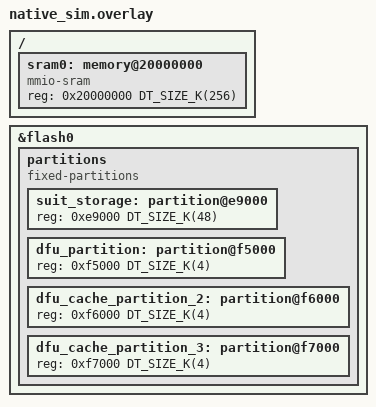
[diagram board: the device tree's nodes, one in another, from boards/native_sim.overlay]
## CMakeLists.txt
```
#
# Copyright (c) 2023 Nordic Semiconductor ASA
#
# SPDX-License-Identifier: LicenseRef-Nordic-5-Clause
#

cmake_minimum_required(VERSION 3.20.0)

find_package(Zephyr REQUIRED HINTS $ENV{ZEPHYR_BASE})

project(integration_test_fetch)
include(../cmake/test_template.cmake)

target_include_directories(app PRIVATE mocks)

zephyr_library_link_libraries(suit_memptr_storage_interface)
zephyr_library_link_libraries(suit_platform_interface)
zephyr_library_link_libraries(suit_ipuc)

zephyr_library_link_libraries_ifdef(CONFIG_TEST_SUIT_PLATFORM_FETCH_VARIANT_APP suit_memory_layout_interface)
zephyr_library_link_libraries_ifdef(CONFIG_TEST_SUIT_PLATFORM_FETCH_VARIANT_SDFW suit_decrypt_test_utils)
zephyr_library_link_libraries_ifdef(CONFIG_TEST_SUIT_PLATFORM_FETCH_VARIANT_SDFW suit_stream_filters_interface)

zephyr_compile_definitions(CONFIG_SOC_NRF54H20_CPUAPP)
```

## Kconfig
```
#
# Copyright (c) 2024 Nordic Semiconductor ASA
#
# SPDX-License-Identifier: LicenseRef-Nordic-5-Clause
#

# Include and define MOCK_* Kconfigs
rsource "../mocks/Kconfig"
rsource "../tests/Kconfig"

choice TEST_SUIT_PLATFORM_FETCH_VARIANT
	prompt "SUIT platform implementation variant to test"
	default TEST_SUIT_PLATFORM_FETCH_VARIANT_SDFW

config TEST_SUIT_PLATFORM_FETCH_VARIANT_APP
	bool "Local or application"
	depends on SUIT_PLATFORM_VARIANT_APP
	select FLASH_IPUC
	select SUIT_ENVELOPE_INFO
	select SUIT_CACHE_RW
	select SUIT_STREAM_SINK_CACHE
	select SUIT_STREAM_FETCH_SOURCE_MGR

config TEST_SUIT_PLATFORM_FETCH_VARIANT_SDFW
	bool "Bootloader or SDFW"
	depends on SUIT_PLATFORM_VARIANT_SDFW
	select MOCK_SDFW_ARBITER
	select SUIT_EXECUTION_MODE
	select SUIT_MCI
	select SUIT_STREAM_FILTER_DECRYPT
	select SUIT_CRYPTO
	select SUIT_STORAGE

endchoice # TEST_SUIT_PLATFORM_FETCH_VARIANT

if TEST_SUIT_PLATFORM_FETCH_VARIANT_APP

config SUIT_CACHE_SDFW_IPUC
	default y

config SUIT_CACHE_SDFW_IPUC_ID
	default 1

config SUIT_CACHE_APP_IPUC
	default y

config SUIT_CACHE_APP_IPUC_ID
	default 255

endif # TEST_SUIT_PLATFORM_FETCH_VARIANT_APP

source "Kconfig.zephyr"
```

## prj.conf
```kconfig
#
# Copyright (c) 2023 Nordic Semiconductor ASA
#
# SPDX-License-Identifier: LicenseRef-Nordic-5-Clause
#

CONFIG_ZTEST=y

CONFIG_SUIT=y
CONFIG_SUIT_PROCESSOR=y
CONFIG_SUIT_PLATFORM=y
CONFIG_SUIT_METADATA=y

CONFIG_SUIT_STREAM=y
CONFIG_SUIT_SINK_SELECTOR=y
CONFIG_SUIT_STREAM_SOURCE_CACHE=y
CONFIG_SUIT_STREAM_SOURCE_MEMPTR=y
CONFIG_SUIT_STREAM_SINK_FLASH=y
CONFIG_SUIT_STREAM_SINK_MEMPTR=y

CONFIG_SUIT_UTILS=y
CONFIG_SUIT_CACHE=y
CONFIG_SUIT_MEMPTR_STORAGE=y

CONFIG_ZCBOR=y
CONFIG_ZCBOR_CANONICAL=y

CONFIG_FLASH=y
CONFIG_FLASH_MAP=y

CONFIG_SUIT_IPUC=y
CONFIG_MOCK_SDFW_ARBITER=y
CONFIG_SUIT_STORAGE=y

CONFIG_SUIT_EXECUTION_MODE=y
CONFIG_SUIT_MCI=y
CONFIG_SUIT_STREAM_FILTER_DECRYPT=y
CONFIG_SUIT_CRYPTO=y
```

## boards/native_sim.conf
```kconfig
#
# Copyright (c) 2025 Nordic Semiconductor ASA
#
# SPDX-License-Identifier: LicenseRef-Nordic-5-Clause
#

CONFIG_FLASH_SIMULATOR=y
CONFIG_FLASH_SIMULATOR_DOUBLE_WRITES=y
```

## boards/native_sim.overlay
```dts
/*
 * Copyright (c) 2025 Nordic Semiconductor ASA
 *
 * SPDX-License-Identifier: LicenseRef-Nordic-5-Clause
 */

&flash0 {
	partitions {
		compatible = "fixed-partitions";
		#address-cells = <1>;
		#size-cells = <1>;

		suit_storage: partition@e9000 {
			reg = <0xe9000 DT_SIZE_K(48)>;
		};

		dfu_partition: partition@f5000 {
			reg = <0xf5000 DT_SIZE_K(4)>;
		};

		dfu_cache_partition_2: partition@f6000 {
			reg = <0xf6000 DT_SIZE_K(4)>;
		};

		dfu_cache_partition_3: partition@f7000 {
			reg = <0xf7000 DT_SIZE_K(4)>;
		};
	};
};

/ {
	sram0: memory@20000000 {
		compatible = "mmio-sram";
		reg = <0x20000000 DT_SIZE_K(256)>;
	};
};
```

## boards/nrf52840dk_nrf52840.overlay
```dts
/*
 * Copyright (c) 2025 Nordic Semiconductor ASA
 *
 * SPDX-License-Identifier: LicenseRef-Nordic-5-Clause
 */

&flash0 {
	partitions {
		compatible = "fixed-partitions";
		#address-cells = <1>;
		#size-cells = <1>;

		/* Use the last 48KB of NVM as suit storage. */
		suit_storage: partition@f4000 {
			reg = <0xf4000 DT_SIZE_K(48)>;
		};
	};
};
```

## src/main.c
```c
/*
 * Copyright (c) 2023 Nordic Semiconductor ASA
 *
 * SPDX-License-Identifier: LicenseRef-Nordic-5-Clause
 */

#include <zephyr/ztest.h>
#include <suit_platform.h>
#include <suit_memptr_storage.h>
#include <suit_platform_internal.h>
#include <suit_dfu_cache.h>

static uint8_t test_data[] = {0,  1,  2,  3,  4,  5,  6,  7,  8,  9,  10, 11, 12, 13, 14, 15,
			      16, 17, 18, 19, 20, 21, 22, 23, 24, 25, 26, 27, 28, 29, 30, 31,
			      32, 33, 34, 35, 36, 37, 38, 39, 40, 41, 42, 43, 44, 45, 46, 47,
			      48, 49, 50, 51, 52, 53, 54, 55, 56, 57, 58, 59, 60, 61, 62, 63};

/*
 * {
 *    "http://source1.com": h'4235623423462346456234623487723572702975',
 *    "http://source2.com.no": h'25672519384710',
 *    "ftp://altsource.com": h'92384859284720'
 * }
 */
static const uint8_t cache[] = {
	0xBF, 0x72, 0x68, 0x74, 0x74, 0x70, 0x3A, 0x2F, 0x2F, 0x73, 0x6F, 0x75, 0x72, 0x63, 0x65,
	0x31, 0x2E, 0x63, 0x6F, 0x6D, 0x54, 0x42, 0x35, 0x62, 0x34, 0x23, 0x46, 0x23, 0x46, 0x45,
	0x62, 0x34, 0x62, 0x34, 0x87, 0x72, 0x35, 0x72, 0x70, 0x29, 0x75, 0x75, 0x68, 0x74, 0x74,
	0x70, 0x3A, 0x2F, 0x2F, 0x73, 0x6F, 0x75, 0x72, 0x63, 0x65, 0x32, 0x2E, 0x63, 0x6F, 0x6D,
	0x2E, 0x6E, 0x6F, 0x47, 0x25, 0x67, 0x25, 0x19, 0x38, 0x47, 0x10, 0x73, 0x66, 0x74, 0x70,
	0x3A, 0x2F, 0x2F, 0x61, 0x6C, 0x74, 0x73, 0x6F, 0x75, 0x72, 0x63, 0x65, 0x2E, 0x63, 0x6F,
	0x6D, 0x47, 0x92, 0x38, 0x48, 0x59, 0x28, 0x47, 0x20, 0xFF};
static const size_t cache_len = sizeof(cache);

/*
 * {
 *    "http://databucket.com": h'4360021135853785764409444542662512368400086117',
 *    "http://storagehole.com": h'053714514299994946548928821768209760220451452304',
 *    "#file.bin": h'12358902317049812091623890476012378490701892365192830986701923'
 * }
 */
static const uint8_t cache2[] = {
	0xA3, 0x75, 0x68, 0x74, 0x74, 0x70, 0x3A, 0x2F, 0x2F, 0x64, 0x61, 0x74, 0x61, 0x62,
	0x75, 0x63, 0x6B, 0x65, 0x74, 0x2E, 0x63, 0x6F, 0x6D, 0x57, 0x43, 0x60, 0x02, 0x11,
	0x35, 0x85, 0x37, 0x85, 0x76, 0x44, 0x09, 0x44, 0x45, 0x42, 0x66, 0x25, 0x12, 0x36,
	0x84, 0x00, 0x08, 0x61, 0x17, 0x76, 0x68, 0x74, 0x74, 0x70, 0x3A, 0x2F, 0x2F, 0x73,
	0x74, 0x6F, 0x72, 0x61, 0x67, 0x65, 0x68, 0x6F, 0x6C, 0x65, 0x2E, 0x63, 0x6F, 0x6D,
	0x58, 0x18, 0x05, 0x37, 0x14, 0x51, 0x42, 0x99, 0x99, 0x49, 0x46, 0x54, 0x89, 0x28,
	0x82, 0x17, 0x68, 0x20, 0x97, 0x60, 0x22, 0x04, 0x51, 0x45, 0x23, 0x04, 0x69, 0x23,
	0x66, 0x69, 0x6C, 0x65, 0x2E, 0x62, 0x69, 0x6E, 0x58, 0x1F, 0x12, 0x35, 0x89, 0x02,
	0x31, 0x70, 0x49, 0x81, 0x20, 0x91, 0x62, 0x38, 0x90, 0x47, 0x60, 0x12, 0x37, 0x84,
	0x90, 0x70, 0x18, 0x92, 0x36, 0x51, 0x92, 0x83, 0x09, 0x86, 0x70, 0x19, 0x23};
static const size_t cache2_len = sizeof(cache2);

/* clang-format off */
static const uint8_t valid_manifest_component[] = {
	0x82, /* array: 2 elements */
		0x4c, /* byte string: 12 bytes */
			0x6b, /* string: 11 characters */
				'I', 'N', 'S', 'T', 'L', 'D', '_', 'M', 'F', 'S', 'T',
		0x50, /* byte string: 16 bytes */
			0x5b, 0x46, 0x9f, 0xd1, 0x90, 0xee, 0x53, 0x9c,
			0xa3, 0x18, 0x68, 0x1b, 0x03, 0x69, 0x5e, 0x36
};
/* clang-format on */

static struct zcbor_string valid_manifest_component_id = {
	.value = valid_manifest_component,
	.len = sizeof(valid_manifest_component),
};

static void setup_cache_with_sample_entries(void)
{
	struct dfu_cache dfu_caches;

	zassert_between_inclusive(2, 1, CONFIG_SUIT_CACHE_MAX_CACHES,
				  "Failed to prepare test fixture: cache istoo small");

	dfu_caches.pools[0].address = (uint8_t *)cache;
	dfu_caches.pools[0].size = (size_t)cache_len;

	dfu_caches.pools[1].address = (uint8_t *)cache2;
	dfu_caches.pools[1].size = (size_t)cache2_len;
	dfu_caches.pools_count = 2;

	suit_dfu_cache_deinitialize();

	suit_plat_err_t rc = suit_dfu_cache_initialize(&dfu_caches);

	zassert_equal(rc, SUIT_PLAT_SUCCESS, "Failed to initialize cache: %i", rc);
}

ZTEST_SUITE(fetch_tests, NULL, NULL, NULL, NULL, NULL);

ZTEST(fetch_tests, test_integrated_fetch_to_memptr_OK)
{
	suit_component_t component_handle;
	memptr_storage_handle_t handle = NULL;
	struct zcbor_string source = {.value = test_data, .len = sizeof(test_data)};
	/* [h'CAND_IMG', h'02'] */
	uint8_t valid_value[] = {0x82, 0x49, 0x68, 'C', 'A',  'N', 'D',
				 '_',  'I',  'M',  'G', 0x41, 0x02};

	struct zcbor_string valid_component_id = {
		.value = valid_value,
		.len = sizeof(valid_value),
	};

	int ret = suit_plat_create_component_handle(&valid_component_id, false, &component_handle);

	zassert_equal(ret, SUIT_SUCCESS, "create_component_handle failed - error %i", ret);

	ret = suit_plat_fetch_integrated(component_handle, &source, &valid_manifest_component_id,
					 NULL);
	zassert_equal(ret, SUIT_SUCCESS, "suit_plat_fetch failed - error %i", ret);

	ret = suit_plat_component_impl_data_get(component_handle, &handle);
	zassert_equal(ret, SUIT_SUCCESS, "suit_plat_component_impl_data_get failed - error %i",
		      ret);

	const uint8_t *payload;
	size_t payload_size = 0;

	ret = suit_memptr_storage_ptr_get(handle, &payload, &payload_size);
	zassert_equal(ret, SUIT_PLAT_SUCCESS, "storage.get failed - error %i", ret);
	zassert_equal(test_data, payload, "Retrieved payload doesn't mach test_data");
	zassert_equal(sizeof(test_data), payload_size,
		      "Retrieved payload_size doesn't mach size of test_data");

	ret = suit_plat_release_component_handle(component_handle);
	zassert_equal(ret, SUIT_SUCCESS, "Handle release failed - error %i", ret);
}

ZTEST(fetch_tests, test_fetch_to_memptr_OK)
{

	suit_component_t component_handle;
	struct zcbor_string uri = {.value = "http://databucket.com",
				   .len = sizeof("http://databucket.com")};
	/* [h'CAND_IMG', h'02'] */
	uint8_t valid_value[] = {0x82, 0x49, 0x68, 'C', 'A',  'N', 'D',
				 '_',  'I',  'M',  'G', 0x41, 0x02};

	struct zcbor_string valid_component_id = {
		.value = valid_value,
		.len = sizeof(valid_value),
	};

	int ret = suit_plat_create_component_handle(&valid_component_id, false, &component_handle);

	zassert_equal(ret, SUIT_SUCCESS, "create_component_handle failed - error %i", ret);

	setup_cache_with_sample_entries();

	ret = suit_plat_fetch(component_handle, &uri, &valid_manifest_component_id, NULL);
	zassert_equal(ret, SUIT_SUCCESS, "suit_plat_fetch failed - error %i", ret);

	ret = suit_plat_release_component_handle(component_handle);
	zassert_equal(ret, SUIT_SUCCESS, "Handle release failed - error %i", ret);

	suit_dfu_cache_deinitialize();
}

ZTEST(fetch_tests, test_fetch_to_memptr_NOK_uri_not_in_cache)
{
	suit_component_t component_handle;
	struct zcbor_string uri = {.value = "http://databucket.no",
				   .len = sizeof("http://databucket.no")};
	/* [h'CAND_IMG', h'02'] */
	uint8_t valid_value[] = {0x82, 0x49, 0x68, 'C', 'A',  'N', 'D',
				 '_',  'I',  'M',  'G', 0x41, 0x02};

	struct zcbor_string valid_component_id = {
		.value = valid_value,
		.len = sizeof(valid_value),
	};

	int ret = suit_plat_create_component_handle(&valid_component_id, false, &component_handle);

	zassert_equal(ret, SUIT_SUCCESS, "create_component_handle failed - error %i", ret);

	setup_cache_with_sample_entries();

	ret = suit_plat_fetch(component_handle, &uri, &valid_manifest_component_id, NULL);
	zassert_equal(ret, SUIT_SUCCESS,
		      "suit_plat_fetch should succeed - supplied uri is not in cache, "
		      "treated as empty payload");

	ret = suit_plat_release_component_handle(component_handle);
	zassert_equal(ret, SUIT_SUCCESS, "Handle release failed - error %i", ret);

	suit_dfu_cache_deinitialize();
}

ZTEST(fetch_tests, test_fetch_to_memptr_NOK_invalid_component_id)
{
	suit_component_t component_handle;
	struct zcbor_string uri = {.value = "http://databucket.com",
				   .len = sizeof("http://databucket.com")};
	/* [h'MEM', h'01', h'1A00080000', h'08'] */
	uint8_t valid_value[] = {0x84, 0x44, 0x63, 'M',	 'E',  'M',  0x41, 0x01,
				 0x45, 0x1A, 0x00, 0x08, 0x00, 0x00, 0x41, 0x08};

	struct zcbor_string valid_component_id = {
		.value = valid_value,
		.len = sizeof(valid_value),
	};

	int ret = suit_plat_create_component_handle(&valid_component_id, false, &component_handle);

	zassert_equal(ret, SUIT_SUCCESS, "create_component_handle failed - error %i", ret);

	setup_cache_with_sample_entries();

	ret = suit_plat_fetch(component_handle, &uri, &valid_manifest_component_id, NULL);
	zassert_not_equal(ret, SUIT_SUCCESS,
			  "suit_plat_fetch should have failed - invalid component_id");

	ret = suit_plat_release_component_handle(component_handle);
	zassert_equal(ret, SUIT_SUCCESS, "Handle release failed - error %i", ret);

	suit_dfu_cache_deinitialize();
}

ZTEST(fetch_tests, test_integrated_fetch_to_memptr_NOK_data_ptr_NULL)
{
	suit_component_t component_handle;
	struct zcbor_string source = {.value = NULL, .len = sizeof(test_data)};
	/* [h'CAND_IMG', h'02'] */
	uint8_t valid_value[] = {0x82, 0x49, 0x68, 'C', 'A',  'N', 'D',
				 '_',  'I',  'M',  'G', 0x41, 0x02};

	struct zcbor_string valid_component_id = {
		.value = valid_value,
		.len = sizeof(valid_value),
	};

	int ret = suit_plat_create_component_handle(&valid_component_id, false, &component_handle);

	zassert_equal(ret, SUIT_SUCCESS, "create_component_handle failed - error %i", ret);

	ret = suit_plat_fetch_integrated(component_handle, &source, &valid_manifest_component_id,
					 NULL);
	zassert_not_equal(ret, SUIT_SUCCESS,
			  "suit_plat_fetch should have failed - NULL data pointer");

	ret = suit_plat_release_component_handle(component_handle);
	zassert_equal(ret, SUIT_SUCCESS, "Handle release failed - error %i", ret);
}

ZTEST(fetch_tests, test_integrated_fetch_to_memptr_NOK_data_size_zero)
{
	suit_component_t component_handle;
	struct zcbor_string source = {.value = test_data, .len = 0};
	/* [h'CAND_IMG', h'02'] */
	uint8_t valid_value[] = {0x82, 0x49, 0x68, 'C', 'A',  'N', 'D',
				 '_',  'I',  'M',  'G', 0x41, 0x02};

	struct zcbor_string valid_component_id = {
		.value = valid_value,
		.len = sizeof(valid_value),
	};

	int ret = suit_plat_create_component_handle(&valid_component_id, false, &component_handle);

	zassert_equal(ret, SUIT_SUCCESS, "create_component_handle failed - error %i", ret);

	ret = suit_plat_fetch_integrated(component_handle, &source, &valid_manifest_component_id,
					 NULL);
	zassert_not_equal(ret, SUIT_SUCCESS, "suit_plat_fetch should have failed - data size 0");

	ret = suit_plat_release_component_handle(component_handle);
	zassert_equal(ret, SUIT_SUCCESS, "Handle release failed - error %i", ret);
}

ZTEST(fetch_tests, test_integrated_fetch_to_memptr_NOK_handle_NULL)
{
	suit_component_t component_handle;
	struct zcbor_string source = {.value = test_data, .len = sizeof(test_data)};
	/* [h'CAND_IMG', h'02'] */
	uint8_t valid_value[] = {0x82, 0x49, 0x68, 'C', 'A',  'N', 'D',
				 '_',  'I',  'M',  'G', 0x41, 0x02};

	struct zcbor_string valid_component_id = {
		.value = valid_value,
		.len = sizeof(valid_value),
	};

	int ret = suit_plat_create_component_handle(&valid_component_id, false, &component_handle);

	zassert_equal(ret, SUIT_SUCCESS, "create_component_handle failed - error %i", ret);

	ret = suit_plat_fetch_integrated(component_handle, &source, &valid_manifest_component_id,
					 NULL);
	zassert_equal(ret, SUIT_SUCCESS, "suit_plat_fetch failed - error %i", ret);

	const uint8_t *payload;
	size_t payload_size = 0;

	ret = suit_memptr_storage_ptr_get(NULL, &payload, &payload_size);
	zassert_not_equal(ret, SUIT_PLAT_SUCCESS,
			  "suit_memptr_storage_get should failed - handle NULL");

	ret = suit_plat_release_component_handle(component_handle);
	zassert_equal(ret, SUIT_SUCCESS, "Handle release failed - error %i", ret);
}
```

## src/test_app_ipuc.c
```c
/*
 * Copyright (c) 2025 Nordic Semiconductor ASA
 *
 * SPDX-License-Identifier: LicenseRef-Nordic-5-Clause
 */

#ifdef CONFIG_TEST_SUIT_PLATFORM_FETCH_VARIANT_APP
#include <zephyr/ztest.h>
#include <suit_platform.h>
#include <dfu/suit_dfu_fetch_source.h>
#include <mock_suit_ipuc.h>
#include <zephyr/fff.h>
#include <suit_dfu_cache_rw.h>
#include <drivers/flash/flash_ipuc.h>
#include <suit_plat_mem_util.h>

#if IS_ENABLED(CONFIG_FLASH)
#if (DT_NODE_EXISTS(DT_CHOSEN(zephyr_flash_controller)))
#define SUIT_PLAT_INTERNAL_NVM_DEV DEVICE_DT_GET(DT_CHOSEN(zephyr_flash_controller))
#else
#define SUIT_PLAT_INTERNAL_NVM_DEV DEVICE_DT_GET(DT_CHOSEN(zephyr_flash))
#endif
#else
#define SUIT_PLAT_INTERNAL_NVM_DEV NULL
#endif

static const uint8_t test_data[] = {0,	1,  2,	3,  4,	5,  6,	7,  8,	9,  10, 11, 12, 13, 14, 15,
				    16, 17, 18, 19, 20, 21, 22, 23, 24, 25, 26, 27, 28, 29, 30, 31,
				    32, 33, 34, 35, 36, 37, 38, 39, 40, 41, 42, 43, 44, 45, 46, 47,
				    48, 49, 50, 51, 52, 53, 54, 55, 56, 57, 58, 59, 60, 61, 62, 63};
static const uint8_t test_data_sdfw[] = {'S', 'D', 'F', 'W', '.', 'b', 'i', 'n'};
static const uint8_t test_data_scfw[] = {'S', 'y', 's', 'C', 't', 'r', 'l', '.', 'b', 'i', 'n'};

/* clang-format off */
static const uint8_t component_rad_0x80000_0x1000[] = {
	0x84, /* array(4) */
		0x44, /* bstr(4) */
			0x63, /* text(3) */
				'M', 'E', 'M',
		0x41, /* bstr(1) */
			0x20, /* Data */
		0x45, /* bstr(5) */
			0x1a, /* uint32 */
				0x00, 0x08, 0x00, 0x00,
		0x43, /* bstr(3) */
			0x19, /* uint16 */
				0x10, 0x00,
};
static const uint8_t component_app_0x90000_0x1000[] = {
	0x84, /* array(4) */
		0x44, /* bstr(4) */
			0x63, /* text(3) */
				'M', 'E', 'M',
		0x41, /* bstr(1) */
			0x20, /* Data */
		0x45, /* bstr(5) */
			0x1a, /* uint32 */
				0x00, 0x09, 0x00, 0x00,
		0x43, /* bstr(3) */
			0x19, /* uint16 */
				0x10, 0x00,
};
/* clang-format on */

static suit_plat_err_t suit_ipuc_get_count_single_fake_func(size_t *count)
{
	zassert_not_null(count, "Caller must provide non-Null pointer");

	*count = 1;

	return SUIT_PLAT_SUCCESS;
}

static suit_plat_err_t
suit_ipuc_get_info_0x80000_0x1000_fake_func(size_t idx, struct zcbor_string *component_id,
					    suit_manifest_role_t *role)
{
	zassert_not_null(component_id, "Caller must provide non-Null pointer to read component_id");
	zassert_not_null(role, "Caller must provide non-Null pointer to read role");
	zassert_equal(idx, 0, "Unexpected idx value");

	component_id->value = component_rad_0x80000_0x1000;
	component_id->len = sizeof(component_rad_0x80000_0x1000);
	*role = SUIT_MANIFEST_RAD_LOCAL_1;

	return SUIT_PLAT_SUCCESS;
}

static suit_plat_err_t suit_ipuc_write_rad_fake_func(struct zcbor_string *component_id,
						     size_t offset, uintptr_t buffer,
						     size_t chunk_size, bool last_chunk)
{
	zassert_not_null(component_id, "Caller must provide non-Null pointer to read component_id");
	zassert_equal(component_id->len, sizeof(component_rad_0x80000_0x1000),
		      "Invalid component ID length passed");
	zassert_equal(memcmp(component_id->value, component_rad_0x80000_0x1000, component_id->len),
		      0, "Invalid component ID value passed");

	return SUIT_PLAT_SUCCESS;
}

static suit_plat_err_t suit_ipuc_get_count_fake_func(size_t *count)
{
	zassert_not_null(count, "Caller must provide non-Null pointer");

	*count = 2;

	return SUIT_PLAT_SUCCESS;
}

static suit_plat_err_t suit_ipuc_get_info_fake_func(size_t idx, struct zcbor_string *component_id,
						    suit_manifest_role_t *role)
{
	zassert_not_null(component_id, "Caller must provide non-Null pointer to read component_id");
	zassert_not_null(role, "Caller must provide non-Null pointer to read role");
	zassert_true(idx < 2, "Unexpected idx value");

	if (idx == 0) {
		component_id->value = component_rad_0x80000_0x1000;
		component_id->len = sizeof(component_rad_0x80000_0x1000);
		*role = SUIT_MANIFEST_RAD_LOCAL_1;
	} else if (idx == 1) {
		component_id->value = component_app_0x90000_0x1000;
		component_id->len = sizeof(component_app_0x90000_0x1000);
		*role = SUIT_MANIFEST_APP_LOCAL_1;
	}

	return SUIT_PLAT_SUCCESS;
}

static suit_plat_err_t suit_ipuc_write_fake_func(struct zcbor_string *component_id, size_t offset,
						 uintptr_t buffer, size_t chunk_size,
						 bool last_chunk)
{
	zassert_not_null(component_id, "Caller must provide non-Null pointer to read component_id");
	zassert_equal(component_id->len, sizeof(component_app_0x90000_0x1000),
		      "Invalid component ID length passed");
	zassert_equal(memcmp(component_id->value, component_app_0x90000_0x1000, component_id->len),
		      0, "Invalid component ID value passed");

	zassert_equal(flash_write(SUIT_PLAT_INTERNAL_NVM_DEV, 0x90000 + offset, (uint8_t *)buffer,
				  chunk_size),
		      0, "Unable to modify NVM to match requested changes");

	return SUIT_PLAT_SUCCESS;
}

static int fetch_request_fn(const uint8_t *uri, size_t uri_length, uint32_t session_id)
{
	int rc = 0;

	if (((uri_length == sizeof("http://databucket.com")) &&
	     memcmp(uri, "http://databucket.com", uri_length) == 0)) {
		zassert_equal(uri_length, sizeof("http://databucket.com"),
			      "Unexpected URI length: %d", uri_length);
		zassert_equal(memcmp(uri, "http://databucket.com", uri_length), 0,
			      "Unexpected URI value");
		rc = suit_dfu_fetch_source_write_fetched_data(session_id, test_data,
							      sizeof(test_data));
	} else if (((uri_length == sizeof("http://databucket.com/sdfw.bin")) &&
		    memcmp(uri, "http://databucket.com/sdfw.bin", uri_length) == 0)) {
		zassert_equal(uri_length, sizeof("http://databucket.com/sdfw.bin"),
			      "Unexpected URI length: %d", uri_length);
		zassert_equal(memcmp(uri, "http://databucket.com/sdfw.bin", uri_length), 0,
			      "Unexpected URI value");
		rc = suit_dfu_fetch_source_write_fetched_data(session_id, test_data_sdfw,
							      sizeof(test_data_sdfw));
	} else if (((uri_length == sizeof("http://databucket.com/scfw.bin")) &&
		    memcmp(uri, "http://databucket.com/scfw.bin", uri_length) == 0)) {
		zassert_equal(uri_length, sizeof("http://databucket.com/scfw.bin"),
			      "Unexpected URI length: %d", uri_length);
		zassert_equal(memcmp(uri, "http://databucket.com/scfw.bin", uri_length), 0,
			      "Unexpected URI value");
		rc = suit_dfu_fetch_source_write_fetched_data(session_id, test_data_scfw,
							      sizeof(test_data_scfw));
	} else {
		zassert_true(false, "Unsupporte URI value");
	}

	if (rc != 0) {
		return SUIT_PLAT_ERR_CRASH;
	}

	return SUIT_PLAT_SUCCESS;
}

static void test_before(void *data)
{
	/* Reset mocks */
	mock_suit_ipuc_reset();

	/* Reset common FFF internal structures */
	FFF_RESET_HISTORY();

	/* Erase NVM area */
	zassert_equal(flash_erase(SUIT_PLAT_INTERNAL_NVM_DEV, 0x90000, 0x1000), 0,
		      "Unable to erase NVM before test execution");

	/* Load IPUCs as SUIT caches */
	suit_ipuc_get_count_fake.custom_fake = suit_ipuc_get_count_fake_func;
	suit_ipuc_get_info_fake.custom_fake = suit_ipuc_get_info_fake_func;

	suit_dfu_cache_rw_init();
	zassert_equal(suit_dfu_cache_0_resize(), SUIT_PLAT_SUCCESS,
		      "Failed to initialize SUIT cache before test execution.");
	zassert_equal(suit_ipuc_get_count_fake.call_count, 2,
		      "Incorrect number of suit_ipuc_get_count() calls (%d)",
		      suit_ipuc_get_count_fake.call_count);
	/* 2x ((count: search for max) + (info of the max)) */
	zassert_equal(suit_ipuc_get_info_fake.call_count, 6,
		      "Incorrect number of suit_ipuc_get_info() calls (%d)",
		      suit_ipuc_get_info_fake.call_count);
	/* Initialization routine must not erase IPUC areas. */
	zassert_equal(suit_ipuc_write_setup_fake.call_count, 0,
		      "Incorrect number of suit_ipuc_write_setup() calls (%d)",
		      suit_ipuc_write_setup_fake.call_count);
	/* Reset mocks */
	mock_suit_ipuc_reset();

	/* Reset common FFF internal structures */
	FFF_RESET_HISTORY();
}

ZTEST_SUITE(fetch_app_mem_tests, NULL, NULL, test_before, NULL, NULL);

ZTEST(fetch_app_mem_tests, test_fetch_to_ipuc_mem_OK)
{
	struct zcbor_string uri = {.value = "http://databucket.com",
				   .len = sizeof("http://databucket.com")};
	/* Create handle that will be used as destination */
	suit_component_t dst_handle;
	/* [h'MEM', h'20', h'1A00080000', h'191000'] */
	uint8_t valid_dst_value[] = {0x84, 0x44, 0x63, 'M',  'E',  'M',	 0x41, 0x20, 0x45,
				     0x1A, 0x00, 0x08, 0x00, 0x00, 0x43, 0x19, 0x10, 0x00};

	struct zcbor_string valid_dst_component_id = {
		.value = valid_dst_value,
		.len = sizeof(valid_dst_value),
	};

	suit_ipuc_get_count_fake.custom_fake = suit_ipuc_get_count_single_fake_func;
	suit_ipuc_get_info_fake.custom_fake = suit_ipuc_get_info_0x80000_0x1000_fake_func;
	suit_ipuc_write_setup_fake.return_val = SUIT_PLAT_SUCCESS;
	suit_ipuc_write_fake.custom_fake = suit_ipuc_write_rad_fake_func;

	zassert_equal(suit_dfu_fetch_source_register(fetch_request_fn), SUIT_PLAT_SUCCESS,
		      "Failed to register fetch source mock");

	int ret = suit_plat_create_component_handle(&valid_dst_component_id, false, &dst_handle);

	zassert_equal(ret, SUIT_SUCCESS, "create_component_handle failed - error %i", ret);

	ret = suit_plat_fetch(dst_handle, &uri, &valid_dst_component_id, NULL);
	zassert_equal(ret, SUIT_SUCCESS, "suit_plat_fetch failed - error %i", ret);

	/* Fetch operation validation. */
	zassert_equal(suit_ipuc_get_count_fake.call_count, 2,
		      "Incorrect number of suit_ipuc_get_count() calls (%d)",
		      suit_ipuc_get_count_fake.call_count);
	zassert_equal(suit_ipuc_get_info_fake.call_count, 2,
		      "Incorrect number of suit_ipuc_get_info() calls (%d)",
		      suit_ipuc_get_info_fake.call_count);
	/* Write into MEM IPUC. */
	zassert_equal(suit_ipuc_write_setup_fake.call_count, 1,
		      "Incorrect number of suit_ipuc_write_setup() calls (%d)",
		      suit_ipuc_write_setup_fake.call_count);
	zassert_equal(suit_ipuc_write_fake.call_count, 2,
		      "Incorrect number of suit_ipuc_write() calls (%d)",
		      suit_ipuc_write_fake.call_count);

	zassert_equal(suit_ipuc_write_fake.arg1_history[0], 0,
		      "Unexpected offset in the first suit_ipuc_write() call (0x%x)",
		      suit_ipuc_write_fake.arg1_history[0]);
	zassert_equal_ptr(suit_ipuc_write_fake.arg2_history[0], test_data,
			  "Unexpected data pointer in the first suit_ipuc_write() call (0x%x)",
			  suit_ipuc_write_fake.arg2_history[0]);
	zassert_equal(suit_ipuc_write_fake.arg3_history[0], sizeof(test_data),
		      "Unexpected data size in the first suit_ipuc_write() call (0x%x)",
		      suit_ipuc_write_fake.arg3_history[0]);
	zassert_equal(suit_ipuc_write_fake.arg4_history[0], false,
		      "Write closed on the first suit_ipuc_write() call");

	zassert_equal(suit_ipuc_write_fake.arg1_history[1], sizeof(test_data),
		      "Unexpected offset in the second suit_ipuc_write() call (0x%x)",
		      suit_ipuc_write_fake.arg1_history[1]);
	zassert_equal_ptr(suit_ipuc_write_fake.arg2_history[1], NULL,
			  "Unexpected data pointer in the second suit_ipuc_write() call (0x%x)",
			  suit_ipuc_write_fake.arg2_history[1]);
	zassert_equal(suit_ipuc_write_fake.arg3_history[1], 0,
		      "Unexpected data size in the second suit_ipuc_write() call (0x%x)",
		      suit_ipuc_write_fake.arg3_history[1]);
	zassert_equal(suit_ipuc_write_fake.arg4_history[1], true,
		      "Write was not closed on the second suit_ipuc_write() call");

	ret = suit_plat_release_component_handle(dst_handle);
	zassert_equal(ret, SUIT_SUCCESS, "dst_handle release failed - error %i", ret);
}

ZTEST_SUITE(fetch_app_cache_tests, NULL, NULL, test_before, NULL, NULL);

ZTEST(fetch_app_cache_tests, test_fetch_to_ipuc_cache_OK)
{
	struct zcbor_string uri = {.value = "http://databucket.com",
				   .len = sizeof("http://databucket.com")};
	/* Create handle that will be used as destination */
	suit_component_t dst_handle;
	/* clang-format off */
	uint8_t valid_dst_value[] = {
		0x82, /* array(2) */
			0x4B, /* bytes(11) */
				0x6A, /* text(10) */
					'C', 'A', 'C', 'H', 'E', '_', 'P', 'O', 'O', 'L',
			0x42, /* bytes(2) */
				0x18, /* uint8_t */
					CONFIG_SUIT_CACHE_APP_IPUC_ID,
	};
	/* clang-format on */
	struct zcbor_string valid_dst_component_id = {
		.value = valid_dst_value,
		.len = sizeof(valid_dst_value),
	};
	size_t cached_size = 0;
	const uint8_t *cached_payload = NULL;

	suit_ipuc_get_count_fake.custom_fake = suit_ipuc_get_count_fake_func;
	suit_ipuc_get_info_fake.custom_fake = suit_ipuc_get_info_fake_func;
	suit_ipuc_write_setup_fake.return_val = SUIT_PLAT_SUCCESS;
	suit_ipuc_write_fake.custom_fake = suit_ipuc_write_fake_func;

	zassert_equal(suit_dfu_fetch_source_register(fetch_request_fn), SUIT_PLAT_SUCCESS,
		      "Failed to register fetch source mock");

	int ret = suit_plat_create_component_handle(&valid_dst_component_id, false, &dst_handle);

	zassert_equal(ret, SUIT_SUCCESS, "create_component_handle failed - error %i", ret);

	ret = suit_plat_fetch(dst_handle, &uri, &valid_dst_component_id, NULL);
	zassert_equal(ret, SUIT_SUCCESS, "suit_plat_fetch failed - error %i", ret);

	/* Fetch operation validation - uses already created IPUC driver instances. */
	zassert_equal(suit_ipuc_get_count_fake.call_count, 0,
		      "Incorrect number of suit_ipuc_get_count() calls (%d)",
		      suit_ipuc_get_count_fake.call_count);
	zassert_equal(suit_ipuc_get_info_fake.call_count, 0,
		      "Incorrect number of suit_ipuc_get_info() calls (%d)",
		      suit_ipuc_get_info_fake.call_count);

	/* Write into APP cache IPUC. */
	zassert_equal(suit_ipuc_write_setup_fake.call_count, 1,
		      "Incorrect number of suit_ipuc_write_setup() calls (%d)",
		      suit_ipuc_write_setup_fake.call_count);
	zassert_true(suit_ipuc_write_fake.call_count >= 4,
		     "Too small number of suit_ipuc_write() calls (%d)",
		     suit_ipuc_write_fake.call_count);

	size_t last_write = suit_ipuc_write_fake.call_count - 1;

	for (size_t i = 0; i < suit_ipuc_write_fake.call_count; i++) {
		printk("\t%d\n", suit_ipuc_write_fake.arg3_history[i]);
		zassert_equal(suit_ipuc_write_fake.arg4_history[i], false,
			      "Write closed too early in suit_ipuc_write() call");
	}

	/* partition header + slot header + URI + (data length) */
	/* data */

	/* slot length */
	zassert_equal(suit_ipuc_write_fake.arg3_history[last_write - 1], 4,
		      "Unexpected data size in the third suit_ipuc_write() call (0x%x)",
		      suit_ipuc_write_fake.arg3_history[last_write - 1]);

	/* slot end marker */
	zassert_equal(suit_ipuc_write_fake.arg3_history[last_write], 1,
		      "Unexpected data size in the fourth suit_ipuc_write() call (0x%x)",
		      suit_ipuc_write_fake.arg3_history[last_write]);

	ret = suit_plat_release_component_handle(dst_handle);
	zassert_equal(ret, SUIT_SUCCESS, "dst_handle release failed - error %i", ret);

	/* Verify the cache contents. */
	zassert_equal(suit_dfu_cache_search(uri.value, uri.len, &cached_payload, &cached_size),
		      SUIT_PLAT_SUCCESS, "Failed to find cached entry inside the SUIT cache");
	zassert_equal(cached_size, sizeof(test_data), "Invalid size of the cached data (%d)",
		      cached_size);
	zassert_equal(memcmp(cached_payload, test_data, sizeof(test_data)), 0,
		      "Invalid cached payload");
}

ZTEST(fetch_app_cache_tests, test_fetch_to_ipuc_cache_sdfw_scfw_OK)
{
	struct zcbor_string uri_sdfw = {.value = "http://databucket.com/sdfw.bin",
					.len = sizeof("http://databucket.com/sdfw.bin")};
	struct zcbor_string uri_scfw = {.value = "http://databucket.com/scfw.bin",
					.len = sizeof("http://databucket.com/scfw.bin")};
	/* Create handle that will be used as destination */
	suit_component_t dst_handle;
	/* clang-format off */
	uint8_t valid_dst_value[] = {
		0x82, /* array(2) */
			0x4B, /* bytes(11) */
				0x6A, /* text(10) */
					'C', 'A', 'C', 'H', 'E', '_', 'P', 'O', 'O', 'L',
			0x41, /* bytes(1) */
				CONFIG_SUIT_CACHE_SDFW_IPUC_ID, /* uint8_t == 0x01 */
	};
	/* clang-format on */
	struct zcbor_string valid_dst_component_id = {
		.value = valid_dst_value,
		.len = sizeof(valid_dst_value),
	};
	size_t cached_size = 0;
	const uint8_t *cached_payload = NULL;

	suit_ipuc_get_count_fake.custom_fake = suit_ipuc_get_count_fake_func;
	suit_ipuc_get_info_fake.custom_fake = suit_ipuc_get_info_fake_func;
	suit_ipuc_write_setup_fake.return_val = SUIT_PLAT_SUCCESS;
	suit_ipuc_write_fake.custom_fake = suit_ipuc_write_fake_func;

	zassert_equal(suit_dfu_fetch_source_register(fetch_request_fn), SUIT_PLAT_SUCCESS,
		      "Failed to register fetch source mock");

	int ret = suit_plat_create_component_handle(&valid_dst_component_id, false, &dst_handle);

	zassert_equal(ret, SUIT_SUCCESS, "create_component_handle failed - error %i", ret);

	/* Fetch SDFW binary */
	ret = suit_plat_fetch(dst_handle, &uri_sdfw, &valid_dst_component_id, NULL);
	zassert_equal(ret, SUIT_SUCCESS, "suit_plat_fetch failed - error %i", ret);

	/* Fetch operation validation - uses already created IPUC driver instances. */
	zassert_equal(suit_ipuc_get_count_fake.call_count, 0,
		      "Incorrect number of suit_ipuc_get_count() calls (%d)",
		      suit_ipuc_get_count_fake.call_count);
	zassert_equal(suit_ipuc_get_info_fake.call_count, 0,
		      "Incorrect number of suit_ipuc_get_info() calls (%d)",
		      suit_ipuc_get_info_fake.call_count);

	/* Write into SDFW cache IPUC. */
	zassert_equal(suit_ipuc_write_setup_fake.call_count, 1,
		      "Incorrect number of suit_ipuc_write_setup() calls (%d)",
		      suit_ipuc_write_setup_fake.call_count);

	/* Fetch SCFW binary using the same IPUC and component context */
	ret = suit_plat_fetch(dst_handle, &uri_scfw, &valid_dst_component_id, NULL);
	zassert_equal(ret, SUIT_SUCCESS, "suit_plat_fetch failed - error %i", ret);

	/* The write_setup call count should remain the same - IPUC must not be erased at this
	 * point.
	 */
	zassert_equal(suit_ipuc_write_setup_fake.call_count, 1,
		      "Incorrect number of suit_ipuc_write_setup() calls (%d)",
		      suit_ipuc_write_setup_fake.call_count);

	ret = suit_plat_release_component_handle(dst_handle);
	zassert_equal(ret, SUIT_SUCCESS, "dst_handle release failed - error %i", ret);

	/* Verify the cache contents. */
	zassert_equal(
		suit_dfu_cache_search(uri_sdfw.value, uri_sdfw.len, &cached_payload, &cached_size),
		SUIT_PLAT_SUCCESS, "Failed to find SDFW entry inside the SUIT cache");
	zassert_equal(cached_size, sizeof(test_data_sdfw), "Invalid SDFW size in cache (%d)",
		      cached_size);
	zassert_equal(memcmp(cached_payload, test_data_sdfw, sizeof(test_data_sdfw)), 0,
		      "Invalid SDFW payload");

	zassert_equal(
		suit_dfu_cache_search(uri_scfw.value, uri_scfw.len, &cached_payload, &cached_size),
		SUIT_PLAT_SUCCESS, "Failed to find SCFW entry inside the SUIT cache");
	zassert_equal(cached_size, sizeof(test_data_scfw), "Invalid SCFW size in cache (%d)",
		      cached_size);
	zassert_equal(memcmp(cached_payload, test_data_scfw, sizeof(test_data_scfw)), 0,
		      "Invalid SCFW payload");
}
#endif /* CONFIG_TEST_SUIT_PLATFORM_FETCH_VARIANT_APP */
```

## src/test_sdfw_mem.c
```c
/*
 * Copyright (c) 2025 Nordic Semiconductor ASA
 *
 * SPDX-License-Identifier: LicenseRef-Nordic-5-Clause
 */

#ifdef CONFIG_TEST_SUIT_PLATFORM_FETCH_VARIANT_SDFW
#include <zephyr/ztest.h>
#include <suit_platform.h>
#include <suit_memptr_storage.h>
#include <suit_platform_internal.h>
#include <suit_dfu_cache.h>
#include <suit_ipuc_sdfw.h>
#include <mocks_sdfw.h>
#include <psa/crypto.h>
#include <suit_decrypt_filter.h>
#include <decrypt_test_utils.h>

static uint8_t test_data[] = {0,  1,  2,  3,  4,  5,  6,  7,  8,  9,  10, 11, 12, 13, 14, 15,
			      16, 17, 18, 19, 20, 21, 22, 23, 24, 25, 26, 27, 28, 29, 30, 31,
			      32, 33, 34, 35, 36, 37, 38, 39, 40, 41, 42, 43, 44, 45, 46, 47,
			      48, 49, 50, 51, 52, 53, 54, 55, 56, 57, 58, 59, 60, 61, 62, 63};

/* clang-format off */
static const uint8_t valid_manifest_component[] = {
	0x82, /* array: 2 elements */
		0x4c, /* byte string: 12 bytes */
			0x6b, /* string: 11 characters */
				'I', 'N', 'S', 'T', 'L', 'D', '_', 'M', 'F', 'S', 'T',
		0x50, /* byte string: 16 bytes */
			0x5b, 0x46, 0x9f, 0xd1, 0x90, 0xee, 0x53, 0x9c,
			0xa3, 0x18, 0x68, 0x1b, 0x03, 0x69, 0x5e, 0x36
};
/* clang-format on */

static struct zcbor_string valid_manifest_component_id = {
	.value = valid_manifest_component,
	.len = sizeof(valid_manifest_component),
};

static void test_before(void *data)
{
	/* Reset mocks */
	mocks_sdfw_reset();

	/* Reset common FFF internal structures */
	FFF_RESET_HISTORY();
}

ZTEST_SUITE(fetch_sdfw_mem_tests, NULL, NULL, test_before, NULL, NULL);

ZTEST(fetch_sdfw_mem_tests, test_integrated_fetch_to_msink_OK)
{
	struct zcbor_string source = {.value = test_data, .len = sizeof(test_data)};
	/* Create handle that will be used as destination */
	suit_component_t dst_handle;
	/* [h'MEM', h'02', h'1A00080000', h'191000'] */
	uint8_t valid_dst_value[] = {0x84, 0x44, 0x63, 'M',  'E',  'M',	 0x41, 0x02, 0x45,
				     0x1A, 0x00, 0x08, 0x00, 0x00, 0x43, 0x19, 0x10, 0x00};

	struct zcbor_string valid_dst_component_id = {
		.value = valid_dst_value,
		.len = sizeof(valid_dst_value),
	};

	int ipc_client_id = 1234;
	int ret = suit_plat_create_component_handle(&valid_dst_component_id, false, &dst_handle);

	zassert_equal(ret, SUIT_SUCCESS, "create_component_handle failed - error %i", ret);
	ret = suit_ipuc_sdfw_write_setup(ipc_client_id, &valid_dst_component_id, NULL, NULL);
	zassert_equal(ret, SUIT_PLAT_ERR_NOT_FOUND, "in-place updateable component found");

	ret = suit_ipuc_sdfw_declare(dst_handle, SUIT_MANIFEST_UNKNOWN);
	zassert_equal(ret, SUIT_PLAT_SUCCESS, "suit_ipuc_sdfw_declare failed - error %i", ret);

	ret = suit_ipuc_sdfw_write_setup(ipc_client_id, &valid_dst_component_id, NULL, NULL);
	zassert_equal(ret, SUIT_PLAT_SUCCESS, "suit_ipuc_sdfw_write_setup failed - error %i", ret);

	ret = suit_plat_fetch_integrated(dst_handle, &source, &valid_dst_component_id, NULL);
	zassert_equal(ret, SUIT_SUCCESS, "suit_plat_fetch failed - error %i", ret);

	ret = suit_ipuc_sdfw_write_setup(ipc_client_id, &valid_dst_component_id, NULL, NULL);
	zassert_equal(ret, SUIT_PLAT_ERR_NOT_FOUND, "in-place updateable component found");

	ret = suit_plat_release_component_handle(dst_handle);
	zassert_equal(ret, SUIT_SUCCESS, "dst_handle release failed - error %i", ret);
}

ZTEST(fetch_tests, test_integrated_fetch_to_msink_encrypted_OK)
{
	suit_component_t component_handle;
	memptr_storage_handle_t handle = NULL;
	struct zcbor_string source = {.value = decrypt_test_ciphertext_direct,
				      .len = sizeof(decrypt_test_ciphertext_direct)};

	/* [h'MEM', h'02', h'1A00080000', h'191000'] */
	uint8_t valid_value[] = {0x84, 0x44, 0x63, 'M',	 'E',  'M',  0x41, 0x02, 0x45,
				 0x1A, 0x00, 0x08, 0x00, 0x00, 0x43, 0x19, 0x10, 0x00};

	struct zcbor_string valid_component_id = {
		.value = valid_value,
		.len = sizeof(valid_value),
	};

	psa_key_id_t cek_key_id;
	uint8_t cek_key_id_cbor[] = {
		0x1A, 0x00, 0x00, 0x00, 0x00,
	};

	psa_status_t status = psa_crypto_init();

	zassert_equal(status, PSA_SUCCESS, "Failed to init psa crypto");

	status = decrypt_test_init_encryption_key(decrypt_test_key_data,
						  sizeof(decrypt_test_key_data), &cek_key_id,
						  PSA_ALG_GCM, cek_key_id_cbor);
	zassert_equal(status, PSA_SUCCESS, "Failed to import key");

	struct suit_encryption_info enc_info = DECRYPT_TEST_ENC_INFO_DEFAULT_INIT(cek_key_id_cbor);

	int ret = suit_plat_create_component_handle(&valid_component_id, false, &component_handle);

	zassert_equal(ret, SUIT_SUCCESS, "create_component_handle failed - error %i", ret);

	ret = suit_plat_fetch_integrated(component_handle, &source, &valid_manifest_component_id,
					 &enc_info);
	zassert_equal(ret, SUIT_SUCCESS, "suit_plat_fetch failed - error %i", ret);

	ret = suit_plat_component_impl_data_get(component_handle, &handle);
	zassert_equal(ret, SUIT_SUCCESS, "suit_plat_component_impl_data_get failed - error %i",
		      ret);

	const uint8_t *payload;
	size_t payload_size = 0;

	ret = suit_memptr_storage_ptr_get(handle, &payload, &payload_size);

	zassert_equal(ret, SUIT_PLAT_SUCCESS, "storage.get failed - error %i", ret);
	zassert_equal(memcmp(decrypt_test_plaintext, payload, strlen(decrypt_test_plaintext)), 0,
		      "Retrieved decrypted payload doesn't mach decrypt_test_plaintext");
	zassert_equal(sizeof(decrypt_test_plaintext), payload_size,
		      "Retrieved payload_size doesn't mach size of decrypt_test_plaintext");

	ret = suit_plat_release_component_handle(component_handle);
	zassert_equal(ret, SUIT_SUCCESS, "Handle release failed - error %i", ret);

	psa_destroy_key(cek_key_id);
}

ZTEST(fetch_tests, test_integrated_fetch_to_memptr_encrypted_NOK)
{
	suit_component_t component_handle;
	struct zcbor_string source = {.value = decrypt_test_ciphertext_direct,
				      .len = sizeof(decrypt_test_ciphertext_direct)};

	/* [h'CAND_IMG', h'02'] */
	uint8_t valid_value[] = {0x82, 0x49, 0x68, 'C', 'A',  'N', 'D',
				 '_',  'I',  'M',  'G', 0x41, 0x02};

	struct zcbor_string valid_component_id = {
		.value = valid_value,
		.len = sizeof(valid_value),
	};

	psa_key_id_t cek_key_id;
	uint8_t cek_key_id_cbor[] = {
		0x1A, 0x00, 0x00, 0x00, 0x00,
	};

	psa_status_t status = psa_crypto_init();

	zassert_equal(status, PSA_SUCCESS, "Failed to init psa crypto");

	status = decrypt_test_init_encryption_key(decrypt_test_key_data,
						  sizeof(decrypt_test_key_data), &cek_key_id,
						  PSA_ALG_GCM, cek_key_id_cbor);
	zassert_equal(status, PSA_SUCCESS, "Failed to import key");

	struct suit_encryption_info enc_info = DECRYPT_TEST_ENC_INFO_DEFAULT_INIT(cek_key_id_cbor);

	int ret = suit_plat_create_component_handle(&valid_component_id, false, &component_handle);

	zassert_equal(ret, SUIT_SUCCESS, "create_component_handle failed - error %i", ret);

	ret = suit_plat_fetch_integrated(component_handle, &source, &valid_manifest_component_id,
					 &enc_info);
	zassert_equal(ret, SUIT_SUCCESS, "suit_plat_fetch failed - error %i", ret);

	ret = suit_plat_release_component_handle(component_handle);
	zassert_equal(ret, SUIT_SUCCESS, "Handle release failed - error %i", ret);

	psa_destroy_key(cek_key_id);
}

ZTEST(fetch_tests, test_integrated_fetch_to_msink_encrypted_wrong_key_NOK)
{
	suit_component_t component_handle;
	memptr_storage_handle_t handle = NULL;
	struct zcbor_string source = {.value = decrypt_test_ciphertext_direct,
				      .len = sizeof(decrypt_test_ciphertext_direct)};

	/* [h'MEM', h'02', h'1A00080000', h'191000'] */
	uint8_t valid_value[] = {0x84, 0x44, 0x63, 'M',	 'E',  'M',  0x41, 0x02, 0x45,
				 0x1A, 0x00, 0x08, 0x00, 0x00, 0x43, 0x19, 0x10, 0x00};

	struct zcbor_string valid_component_id = {
		.value = valid_value,
		.len = sizeof(valid_value),
	};

	psa_key_id_t cek_key_id;
	uint8_t cek_key_id_cbor[] = {
		0x1A, 0x00, 0x00, 0x00, 0x00,
	};

	psa_status_t status = psa_crypto_init();

	zassert_equal(status, PSA_SUCCESS, "Failed to init psa crypto");

	uint8_t wrong_test_key_data[sizeof(decrypt_test_key_data)];

	memcpy(wrong_test_key_data, decrypt_test_key_data, sizeof(wrong_test_key_data));
	/* Corrupt CEK that we store.*/
	wrong_test_key_data[10] = 0x00;

	status = decrypt_test_init_encryption_key(wrong_test_key_data, sizeof(wrong_test_key_data),
						  &cek_key_id, PSA_ALG_GCM, cek_key_id_cbor);
	zassert_equal(status, PSA_SUCCESS, "Failed to import key");

	struct suit_encryption_info enc_info = DECRYPT_TEST_ENC_INFO_DEFAULT_INIT(cek_key_id_cbor);

	int ret = suit_plat_create_component_handle(&valid_component_id, false, &component_handle);

	zassert_equal(ret, SUIT_SUCCESS, "create_component_handle failed - error %i", ret);

	ret = suit_plat_fetch_integrated(component_handle, &source, &valid_manifest_component_id,
					 &enc_info);
	zassert_equal(ret, SUIT_ERR_AUTHENTICATION,
		      "suit_plat_fetch should have failed with SUIT_ERR_AUTHENTICATION");

	ret = suit_plat_component_impl_data_get(component_handle, &handle);
	zassert_equal(ret, SUIT_SUCCESS, "suit_plat_component_impl_data_get failed - error %i",
		      ret);

	const uint8_t *payload;
	size_t payload_size = 0;

	ret = suit_memptr_storage_ptr_get(handle, &payload, &payload_size);

	zassert_equal(ret, SUIT_PLAT_SUCCESS, "storage.get failed - error %i", ret);
	zassert_not_equal(memcmp(decrypt_test_plaintext, payload, strlen(decrypt_test_plaintext)),
			  0, "Retrieved decrypted payload should not mach decrypt_test_plaintext");
	zassert_equal(payload_size, 0, "Retrieved payload_size is not 0");

	ret = suit_plat_release_component_handle(component_handle);
	zassert_equal(ret, SUIT_SUCCESS, "Handle release failed - error %i", ret);

	psa_destroy_key(cek_key_id);
}
#endif /* CONFIG_TEST_SUIT_PLATFORM_FETCH_VARIANT_SDFW */
```
